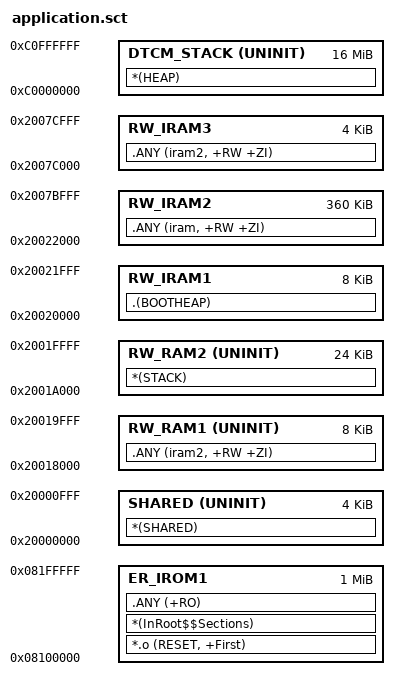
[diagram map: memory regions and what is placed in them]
; *************************************************************
; *** Scatter-Loading Description File generated by uVision ***
; *************************************************************
LR_IROM1 0x08100000 0x000100000  {    ; load region size_region
  ER_IROM1 0x08100000 0x00100000  {  ; load address = execution address
   *.o (RESET, +First)
   *(InRoot$$Sections)
   .ANY (+RO)
  }
  SHARED 0x20000000 UNINIT 0x00001000  {  ; DTCM
    *(SHARED)
  }
  RW_IRAM1 0x20020000 0x00002000  {  ; RW data
   .(BOOTHEAP)
  }
  RW_IRAM2 0x20022000 0x0005A000  {  ; RW data
   .ANY (iram, +RW +ZI)
  }
  RW_IRAM3 0x2007C000 0x00001000  {  ; RW data
   .ANY (iram2, +RW +ZI)
  }
  RW_RAM1 0x20018000 UNINIT 0x00002000  { ; RW data
   .ANY (iram2, +RW +ZI)
  }
  RW_RAM2 0x2001A000 UNINIT 0x00006000  { ; STACK
   *(STACK)
  }
  DTCM_STACK 0xC0000000 UNINIT 0x01000000  {  ; SDRAM
   *(HEAP)
  }
}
